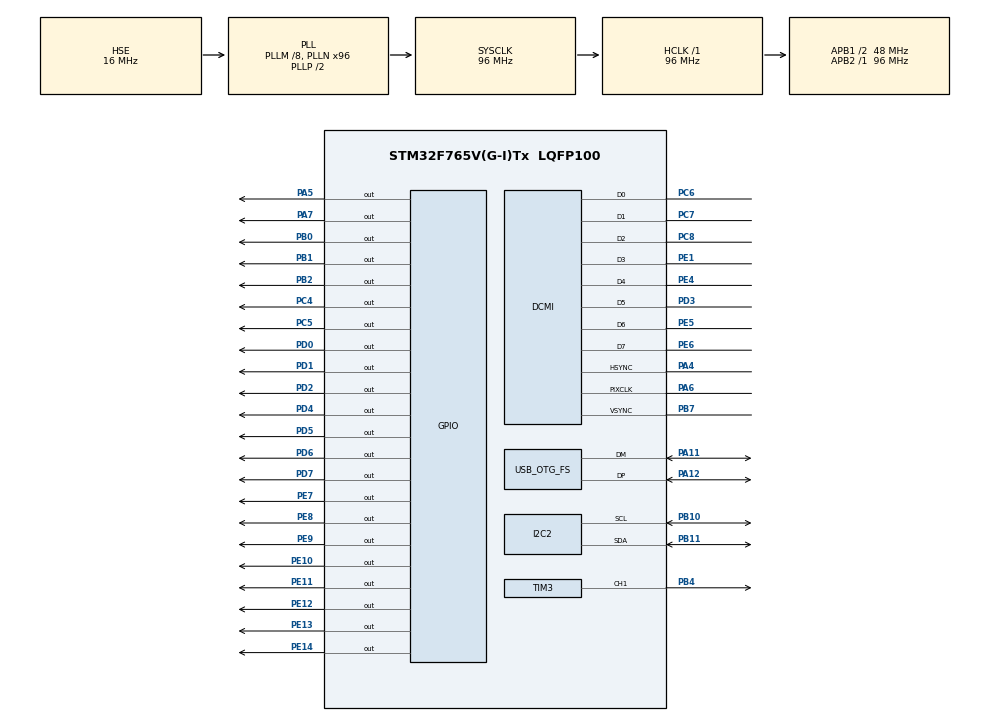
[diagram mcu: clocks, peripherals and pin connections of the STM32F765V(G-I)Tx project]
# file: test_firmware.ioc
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CORTEX_M7.default_mode_Activation=1
DCMI.JPEGMode=DCMI_JPEG_DISABLE
DCMI.PCKPolarity=DCMI_PCKPOLARITY_RISING
DCMI.VSPolarity=DCMI_VSPOLARITY_HIGH
Dma.DCMI.0.Direction=DMA_PERIPH_TO_MEMORY
Dma.DCMI.0.FIFOMode=DMA_FIFOMODE_DISABLE
Dma.DCMI.0.Instance=DMA2_Stream1
Dma.DCMI.0.MemDataAlignment=DMA_MDATAALIGN_WORD
Dma.DCMI.0.MemInc=DMA_MINC_ENABLE
Dma.DCMI.0.Mode=DMA_NORMAL
Dma.DCMI.0.PeriphDataAlignment=DMA_PDATAALIGN_WORD
Dma.DCMI.0.PeriphInc=DMA_PINC_DISABLE
Dma.DCMI.0.Priority=DMA_PRIORITY_LOW
Dma.Request0=DCMI
I2C2.Timing=0x20303E5D
Mcu.Family=STM32F7
Mcu.Name=STM32F765V(G-I)Tx
Mcu.Package=LQFP100
NVIC.DCMI_IRQn=true\:0\:0\:false\:false\:true\:true\:true\:true
NVIC.DMA2_Stream1_IRQn=true\:0\:0\:false\:false\:true\:false\:true\:true
NVIC.OTG_FS_IRQn=true\:0\:0\:false\:false\:true\:false\:true\:true
NVIC.PriorityGroup=NVIC_PRIORITYGROUP_4
PA11.Mode=Device_Only
PA11.Signal=USB_OTG_FS_DM
PA12.Mode=Device_Only
PA12.Signal=USB_OTG_FS_DP
PA13.Mode=Trace_Asynchronous_SW
PA13.Signal=SYS_JTMS-SWDIO
PA14.Mode=Trace_Asynchronous_SW
PA14.Signal=SYS_JTCK-SWCLK
PA4.GPIO_PuPd=GPIO_PULLUP
PA4.GPIO_Speed=GPIO_SPEED_FREQ_VERY_HIGH
PA4.Mode=Slave_8_bits_External_Synchro
PA4.Signal=DCMI_HSYNC
PA5.Signal=GPIO_Output
PA6.GPIO_PuPd=GPIO_PULLUP
PA6.GPIO_Speed=GPIO_SPEED_FREQ_VERY_HIGH
PA6.Mode=Slave_8_bits_External_Synchro
PA6.Signal=DCMI_PIXCLK
PA7.Signal=GPIO_Output
PB0.Signal=GPIO_Output
PB1.Signal=GPIO_Output
PB10.Mode=I2C
PB10.Signal=I2C2_SCL
PB11.Mode=I2C
PB11.Signal=I2C2_SDA
PB2.Signal=GPIO_Output
PB3.Mode=Trace_Asynchronous_SW
PB3.Signal=SYS_JTDO-SWO
PB4.Signal=S_TIM3_CH1
PB7.GPIO_PuPd=GPIO_PULLUP
PB7.GPIO_Speed=GPIO_SPEED_FREQ_VERY_HIGH
PB7.Mode=Slave_8_bits_External_Synchro
PB7.Signal=DCMI_VSYNC
PC4.Signal=GPIO_Output
PC5.Signal=GPIO_Output
PC6.GPIO_PuPd=GPIO_PULLUP
PC6.GPIO_Speed=GPIO_SPEED_FREQ_VERY_HIGH
PC6.Mode=Slave_8_bits_External_Synchro
PC6.Signal=DCMI_D0
PC7.GPIO_PuPd=GPIO_PULLUP
PC7.GPIO_Speed=GPIO_SPEED_FREQ_VERY_HIGH
PC7.Mode=Slave_8_bits_External_Synchro
PC7.Signal=DCMI_D1
PC8.GPIO_PuPd=GPIO_PULLUP
PC8.GPIO_Speed=GPIO_SPEED_FREQ_VERY_HIGH
PC8.Mode=Slave_8_bits_External_Synchro
PC8.Signal=DCMI_D2
PD0.Signal=GPIO_Output
PD1.Signal=GPIO_Output
PD2.Signal=GPIO_Output
PD3.GPIO_PuPd=GPIO_PULLUP
PD3.GPIO_Speed=GPIO_SPEED_FREQ_VERY_HIGH
PD3.Mode=Slave_8_bits_External_Synchro
PD3.Signal=DCMI_D5
PD4.Signal=GPIO_Output
PD5.Signal=GPIO_Output
PD6.Signal=GPIO_Output
PD7.Signal=GPIO_Output
PE1.GPIO_PuPd=GPIO_PULLUP
PE1.GPIO_Speed=GPIO_SPEED_FREQ_VERY_HIGH
PE1.Mode=Slave_8_bits_External_Synchro
PE1.Signal=DCMI_D3
PE10.Signal=GPIO_Output
PE11.Signal=GPIO_Output
PE12.Signal=GPIO_Output
PE13.Signal=GPIO_Output
PE14.Signal=GPIO_Output
PE4.GPIO_PuPd=GPIO_PULLUP
PE4.GPIO_Speed=GPIO_SPEED_FREQ_VERY_HIGH
PE4.Mode=Slave_8_bits_External_Synchro
PE4.Signal=DCMI_D4
PE5.GPIO_PuPd=GPIO_PULLUP
PE5.GPIO_Speed=GPIO_SPEED_FREQ_VERY_HIGH
PE5.Mode=Slave_8_bits_External_Synchro
PE5.Signal=DCMI_D6
PE6.GPIO_PuPd=GPIO_PULLUP
PE6.GPIO_Speed=GPIO_SPEED_FREQ_VERY_HIGH
PE6.Mode=Slave_8_bits_External_Synchro
PE6.Signal=DCMI_D7
PE7.Signal=GPIO_Output
PE8.Signal=GPIO_Output
PE9.Signal=GPIO_Output
PH0/OSC_IN.Mode=HSE-External-Oscillator
PH0/OSC_IN.Signal=RCC_OSC_IN
PH1/OSC_OUT.Mode=HSE-External-Oscillator
PH1/OSC_OUT.Signal=RCC_OSC_OUT
ProjectManager.HeapSize=0x200
ProjectManager.StackSize=0x400
ProjectManager.TargetToolchain=STM32CubeIDE
RCC.AHBFreq_Value=96000000
RCC.APB1CLKDivider=RCC_HCLK_DIV2
RCC.APB1Freq_Value=48000000
RCC.APB1TimFreq_Value=96000000
RCC.APB2Freq_Value=96000000
RCC.APB2TimFreq_Value=96000000
RCC.CortexFreq_Value=96000000
RCC.HCLKFreq_Value=96000000
RCC.HSE_VALUE=16000000
RCC.HSI_VALUE=16000000
RCC.LSE_VALUE=32768
RCC.PLLM=8
RCC.PLLN=96
RCC.PLLQ=4
RCC.SYSCLKFreq_VALUE=96000000
RCC.SYSCLKSource=RCC_SYSCLKSOURCE_PLLCLK
RCC.USBFreq_Value=48000000
RCC.VCOOutputFreq_Value=192000000
SH.S_TIM3_CH1.0=TIM3_CH1,PWM Generation1 CH1
TIM3.AutoReloadPreload=TIM_AUTORELOAD_PRELOAD_ENABLE
TIM3.Channel-PWM\ Generation1\ CH1=TIM_CHANNEL_1
TIM3.Period=255
TIM3.Prescaler=96-1
TIM3.Pulse-PWM\ Generation1\ CH1=25
USB_DEVICE.CLASS_NAME_FS=CDC
USB_DEVICE.VirtualMode-CDC_FS=Cdc
USB_DEVICE.VirtualModeFS=Cdc_FS
USB_OTG_FS.VirtualMode=Device_Only
VP_TIM3_VS_ClockSourceINT.Mode=Internal
VP_USB_DEVICE_VS_USB_DEVICE_CDC_FS.Mode=CDC_FS
board=custom

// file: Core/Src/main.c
/* USER CODE BEGIN Header */
/**
  ******************************************************************************
  * @file           : main.c
  * @brief          : Main program body
  ******************************************************************************
  * @attention
  *
  * Copyright (c) 2026 STMicroelectronics.
  * All rights reserved.
  *
  * This software is licensed under terms that can be found in the LICENSE file
  * in the root directory of this software component.
  * If no LICENSE file comes with this software, it is provided AS-IS.
  *
  ******************************************************************************
  */
/* USER CODE END Header */
#include "main.h"
#include "usb_device.h"

DCMI_HandleTypeDef hdcmi;
DMA_HandleTypeDef hdma_dcmi;

I2C_HandleTypeDef hi2c2;

TIM_HandleTypeDef htim3;

void SystemClock_Config(void);
static void MPU_Config(void);
static void MX_GPIO_Init(void);
static void MX_DMA_Init(void);
static void MX_DCMI_Init(void);
static void MX_I2C2_Init(void);
static void MX_TIM3_Init(void);

int main(void)
{

  /* MPU Configuration--------------------------------------------------------*/
  MPU_Config();

  /* MCU Configuration--------------------------------------------------------*/

  /* Reset of all peripherals, Initializes the Flash interface and the Systick. */
  HAL_Init();

  /* Configure the system clock */
  SystemClock_Config();

  /* Initialize all configured peripherals */
  MX_GPIO_Init();
  MX_DMA_Init();
  MX_DCMI_Init();
  MX_USB_DEVICE_Init();
  MX_I2C2_Init();
  MX_TIM3_Init();

  /* Infinite loop */
  /* USER CODE BEGIN WHILE */
  while (1)
  {
	  HAL_GPIO_TogglePin(GPIOB, GPIO_PIN_4);
	  HAL_Delay(2000);

    /* USER CODE END WHILE */

  }
}

void SystemClock_Config(void)
{
  RCC_OscInitTypeDef RCC_OscInitStruct = {0};
  RCC_ClkInitTypeDef RCC_ClkInitStruct = {0};

  /** Configure the main internal regulator output voltage
  */
  __HAL_RCC_PWR_CLK_ENABLE();
  __HAL_PWR_VOLTAGESCALING_CONFIG(PWR_REGULATOR_VOLTAGE_SCALE3);

  /** Initializes the RCC Oscillators according to the specified parameters
  * in the RCC_OscInitTypeDef structure.
  */
  RCC_OscInitStruct.OscillatorType = RCC_OSCILLATORTYPE_HSE;
  RCC_OscInitStruct.HSEState = RCC_HSE_ON;
  RCC_OscInitStruct.PLL.PLLState = RCC_PLL_ON;
  RCC_OscInitStruct.PLL.PLLSource = RCC_PLLSOURCE_HSE;
  RCC_OscInitStruct.PLL.PLLM = 8;
  RCC_OscInitStruct.PLL.PLLN = 96;
  RCC_OscInitStruct.PLL.PLLP = RCC_PLLP_DIV2;
  RCC_OscInitStruct.PLL.PLLQ = 4;
  RCC_OscInitStruct.PLL.PLLR = 2;
  if (HAL_RCC_OscConfig(&RCC_OscInitStruct) != HAL_OK)
  {
    Error_Handler();
  }

  /** Activate the Over-Drive mode
  */
  if (HAL_PWREx_EnableOverDrive() != HAL_OK)
  {
    Error_Handler();
  }

  /** Initializes the CPU, AHB and APB buses clocks
  */
  RCC_ClkInitStruct.ClockType = RCC_CLOCKTYPE_HCLK|RCC_CLOCKTYPE_SYSCLK
                              |RCC_CLOCKTYPE_PCLK1|RCC_CLOCKTYPE_PCLK2;
  RCC_ClkInitStruct.SYSCLKSource = RCC_SYSCLKSOURCE_PLLCLK;
  RCC_ClkInitStruct.AHBCLKDivider = RCC_SYSCLK_DIV1;
  RCC_ClkInitStruct.APB1CLKDivider = RCC_HCLK_DIV2;
  RCC_ClkInitStruct.APB2CLKDivider = RCC_HCLK_DIV1;

  if (HAL_RCC_ClockConfig(&RCC_ClkInitStruct, FLASH_LATENCY_3) != HAL_OK)
  {
    Error_Handler();
  }
}

static void MX_DCMI_Init(void)
{

  hdcmi.Instance = DCMI;
  hdcmi.Init.SynchroMode = DCMI_SYNCHRO_HARDWARE;
  hdcmi.Init.PCKPolarity = DCMI_PCKPOLARITY_RISING;
  hdcmi.Init.VSPolarity = DCMI_VSPOLARITY_HIGH;
  hdcmi.Init.HSPolarity = DCMI_HSPOLARITY_LOW;
  hdcmi.Init.CaptureRate = DCMI_CR_ALL_FRAME;
  hdcmi.Init.ExtendedDataMode = DCMI_EXTEND_DATA_8B;
  hdcmi.Init.JPEGMode = DCMI_JPEG_DISABLE;
  hdcmi.Init.ByteSelectMode = DCMI_BSM_ALL;
  hdcmi.Init.ByteSelectStart = DCMI_OEBS_ODD;
  hdcmi.Init.LineSelectMode = DCMI_LSM_ALL;
  hdcmi.Init.LineSelectStart = DCMI_OELS_ODD;
  if (HAL_DCMI_Init(&hdcmi) != HAL_OK)
  {
    Error_Handler();
  }

}

static void MX_I2C2_Init(void)
{

  hi2c2.Instance = I2C2;
  hi2c2.Init.Timing = 0x20303E5D;
  hi2c2.Init.OwnAddress1 = 0;
  hi2c2.Init.AddressingMode = I2C_ADDRESSINGMODE_7BIT;
  hi2c2.Init.DualAddressMode = I2C_DUALADDRESS_DISABLE;
  hi2c2.Init.OwnAddress2 = 0;
  hi2c2.Init.OwnAddress2Masks = I2C_OA2_NOMASK;
  hi2c2.Init.GeneralCallMode = I2C_GENERALCALL_DISABLE;
  hi2c2.Init.NoStretchMode = I2C_NOSTRETCH_DISABLE;
  if (HAL_I2C_Init(&hi2c2) != HAL_OK)
  {
    Error_Handler();
  }

  /** Configure Analogue filter
  */
  if (HAL_I2CEx_ConfigAnalogFilter(&hi2c2, I2C_ANALOGFILTER_ENABLE) != HAL_OK)
  {
    Error_Handler();
  }

  /** Configure Digital filter
  */
  if (HAL_I2CEx_ConfigDigitalFilter(&hi2c2, 0) != HAL_OK)
  {
    Error_Handler();
  }

}

static void MX_TIM3_Init(void)
{

  TIM_ClockConfigTypeDef sClockSourceConfig = {0};
  TIM_MasterConfigTypeDef sMasterConfig = {0};

  htim3.Instance = TIM3;
  htim3.Init.Prescaler = 96-1;
  htim3.Init.CounterMode = TIM_COUNTERMODE_UP;
  htim3.Init.Period = 65536-1;
  htim3.Init.ClockDivision = TIM_CLOCKDIVISION_DIV1;
  htim3.Init.AutoReloadPreload = TIM_AUTORELOAD_PRELOAD_DISABLE;
  if (HAL_TIM_Base_Init(&htim3) != HAL_OK)
  {
    Error_Handler();
  }
  sClockSourceConfig.ClockSource = TIM_CLOCKSOURCE_INTERNAL;
  if (HAL_TIM_ConfigClockSource(&htim3, &sClockSourceConfig) != HAL_OK)
  {
    Error_Handler();
  }
  sMasterConfig.MasterOutputTrigger = TIM_TRGO_RESET;
  sMasterConfig.MasterSlaveMode = TIM_MASTERSLAVEMODE_DISABLE;
  if (HAL_TIMEx_MasterConfigSynchronization(&htim3, &sMasterConfig) != HAL_OK)
  {
    Error_Handler();
  }

}

static void MX_DMA_Init(void)
{

  /* DMA controller clock enable */
  __HAL_RCC_DMA2_CLK_ENABLE();

  /* DMA interrupt init */
  /* DMA2_Stream1_IRQn interrupt configuration */
  HAL_NVIC_SetPriority(DMA2_Stream1_IRQn, 0, 0);
  HAL_NVIC_EnableIRQ(DMA2_Stream1_IRQn);

}

static void MX_GPIO_Init(void)
{
  GPIO_InitTypeDef GPIO_InitStruct = {0};

  /* GPIO Ports Clock Enable */
  __HAL_RCC_GPIOE_CLK_ENABLE();
  __HAL_RCC_GPIOH_CLK_ENABLE();
  __HAL_RCC_GPIOA_CLK_ENABLE();
  __HAL_RCC_GPIOC_CLK_ENABLE();
  __HAL_RCC_GPIOB_CLK_ENABLE();
  __HAL_RCC_GPIOD_CLK_ENABLE();

  /*Configure GPIO pin Output Level */
  HAL_GPIO_WritePin(GPIOA, GPIO_PIN_5|GPIO_PIN_7, GPIO_PIN_RESET);

  /*Configure GPIO pin Output Level */
  HAL_GPIO_WritePin(GPIOC, GPIO_PIN_4|GPIO_PIN_5, GPIO_PIN_RESET);

  /*Configure GPIO pin Output Level */
  HAL_GPIO_WritePin(GPIOB, GPIO_PIN_0|GPIO_PIN_1|GPIO_PIN_2|GPIO_PIN_3, GPIO_PIN_RESET);

  /*Configure GPIO pin Output Level */
  HAL_GPIO_WritePin(GPIOE, GPIO_PIN_7|GPIO_PIN_8|GPIO_PIN_9|GPIO_PIN_10
                          |GPIO_PIN_11|GPIO_PIN_12|GPIO_PIN_13|GPIO_PIN_14, GPIO_PIN_RESET);

  /*Configure GPIO pin Output Level */
  HAL_GPIO_WritePin(GPIOD, GPIO_PIN_0|GPIO_PIN_1|GPIO_PIN_2|GPIO_PIN_4
                          |GPIO_PIN_5|GPIO_PIN_6|GPIO_PIN_7, GPIO_PIN_RESET);

  /*Configure GPIO pins : PA5 PA7 */
  GPIO_InitStruct.Pin = GPIO_PIN_5|GPIO_PIN_7;
  GPIO_InitStruct.Mode = GPIO_MODE_OUTPUT_PP;
  GPIO_InitStruct.Pull = GPIO_NOPULL;
  GPIO_InitStruct.Speed = GPIO_SPEED_FREQ_LOW;
  HAL_GPIO_Init(GPIOA, &GPIO_InitStruct);

  /*Configure GPIO pins : PC4 PC5 */
  GPIO_InitStruct.Pin = GPIO_PIN_4|GPIO_PIN_5;
  GPIO_InitStruct.Mode = GPIO_MODE_OUTPUT_PP;
  GPIO_InitStruct.Pull = GPIO_NOPULL;
  GPIO_InitStruct.Speed = GPIO_SPEED_FREQ_LOW;
  HAL_GPIO_Init(GPIOC, &GPIO_InitStruct);

  /*Configure GPIO pins : PB0 PB1 PB2 PB3 */
  GPIO_InitStruct.Pin = GPIO_PIN_0|GPIO_PIN_1|GPIO_PIN_2|GPIO_PIN_3;
  GPIO_InitStruct.Mode = GPIO_MODE_OUTPUT_PP;
  GPIO_InitStruct.Pull = GPIO_NOPULL;
  GPIO_InitStruct.Speed = GPIO_SPEED_FREQ_LOW;
  HAL_GPIO_Init(GPIOB, &GPIO_InitStruct);

  /*Configure GPIO pins : PE7 PE8 PE9 PE10
                           PE11 PE12 PE13 PE14 */
  GPIO_InitStruct.Pin = GPIO_PIN_7|GPIO_PIN_8|GPIO_PIN_9|GPIO_PIN_10
                          |GPIO_PIN_11|GPIO_PIN_12|GPIO_PIN_13|GPIO_PIN_14;
  GPIO_InitStruct.Mode = GPIO_MODE_OUTPUT_PP;
  GPIO_InitStruct.Pull = GPIO_NOPULL;
  GPIO_InitStruct.Speed = GPIO_SPEED_FREQ_LOW;
  HAL_GPIO_Init(GPIOE, &GPIO_InitStruct);

  /*Configure GPIO pins : PD0 PD1 PD2 PD4
                           PD5 PD6 PD7 */
  GPIO_InitStruct.Pin = GPIO_PIN_0|GPIO_PIN_1|GPIO_PIN_2|GPIO_PIN_4
                          |GPIO_PIN_5|GPIO_PIN_6|GPIO_PIN_7;
  GPIO_InitStruct.Mode = GPIO_MODE_OUTPUT_PP;
  GPIO_InitStruct.Pull = GPIO_NOPULL;
  GPIO_InitStruct.Speed = GPIO_SPEED_FREQ_LOW;
  HAL_GPIO_Init(GPIOD, &GPIO_InitStruct);

}

 /* MPU Configuration */

void MPU_Config(void)
{
  MPU_Region_InitTypeDef MPU_InitStruct = {0};

  /* Disables the MPU */
  HAL_MPU_Disable();

  /** Initializes and configures the Region and the memory to be protected
  */
  MPU_InitStruct.Enable = MPU_REGION_ENABLE;
  MPU_InitStruct.Number = MPU_REGION_NUMBER0;
  MPU_InitStruct.BaseAddress = 0x0;
  MPU_InitStruct.Size = MPU_REGION_SIZE_4GB;
  MPU_InitStruct.SubRegionDisable = 0x87;
  MPU_InitStruct.TypeExtField = MPU_TEX_LEVEL0;
  MPU_InitStruct.AccessPermission = MPU_REGION_NO_ACCESS;
  MPU_InitStruct.DisableExec = MPU_INSTRUCTION_ACCESS_DISABLE;
  MPU_InitStruct.IsShareable = MPU_ACCESS_SHAREABLE;
  MPU_InitStruct.IsCacheable = MPU_ACCESS_NOT_CACHEABLE;
  MPU_InitStruct.IsBufferable = MPU_ACCESS_NOT_BUFFERABLE;

  HAL_MPU_ConfigRegion(&MPU_InitStruct);
  /* Enables the MPU */
  HAL_MPU_Enable(MPU_PRIVILEGED_DEFAULT);

}

void Error_Handler(void)
{
  __disable_irq();
  while (1)
  {
  }
}
